# NUC400_v1 register map
File version: 1.0
Registers are 32-bit, read-write, reset 0x0 unless marked. A register's access mark holds for its fields unless they carry their own. Offsets are from the block's base; [hi:lo] are bit positions.

## CRC — CRC Register Map
Base 0x40031000
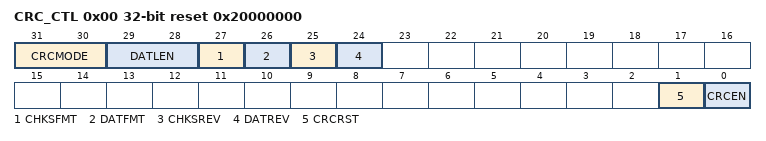
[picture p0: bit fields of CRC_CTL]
0x00 CRC_CTL reset 0x20000000 — CRC Control Register
  [31:30] CRCMODE — CRC Polynomial Mode Selection
    0=CRC-CCITT Polynomial mode; 1=CRC-8 Polynomial mode; 2=CRC-16 Polynomial mode; 3=CRC-32 Polynomial mode
  [29:28] DATLEN — CPU Write Data Length. This field indicates the write data length. Note: When the data length is 8-bit mode, the valid data is DATA [7:0]; if the data length is 16-bit mode, the valid data is DATA [15:0].
    0=Data length is 8-bit mode; 1=Data length is 16-bit mode. Data length is 32-bit mode
  [27] CHKSFMT — Checksum Complement
    0=No bit order reverse for CRC checksum; 1=1's complement for CRC checksum
  [26] DATFMT — Write Data Complement
    0=No bit order reversed for CRC write data in; 1=1's complement for CRC write data in
  [25] CHKSREV — Checksum Reverse. Note: If the checksum data is 0XDD7B0F2E, the bit order reversed for CRC checksum is 0x74F0DEBB.
    0=No bit order reverse for CRC checksum; 1=Bit order reverse for CRC checksum
  [24] DATREV — Write Data Order Reverse. Note: If the write data is 0xAABBCCDD, the bit order reverse for CRC write data in is 0x55DD33BB
    0=No bit order reversed for CRC write data in; 1=Bit order reversed for CRC write data in (per byte)
  [1] CRCRST — CRC Engine Reset. Note: Setting this bit will reload the initial seed value.
    0=No effect; 1=Reset the internal CRC state machine and internal buffer. The contents of control register will not be cleared. This bit will automatically be cleared after few clock cycles
  [0] CRCEN — CRC Channel Enable Bit
    0=CRC function Disabled; 1=CRC function Enabled
0x04 CRC_DAT — CRC Write Data Register
  [31:0] DATA — CRC Write Data Bits. Software can write data to this field to perform CRC operation, or uses PDMA function to get the data from memory
0x08 CRC_SEED reset 0xFFFFFFFF
  [31:0] SEED — CRC Seed Bits. This field indicates the CRC seed value.
0x0C CRC_CHECKSUM ro
  [31:0] CHECKSUM — CRC Checksum Bits. This field indicates the CRC checksum.

## OPA — OPS Register Map
Base 0x40046000
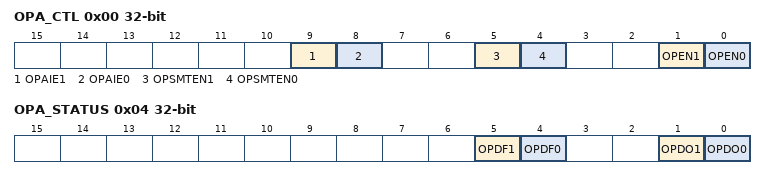
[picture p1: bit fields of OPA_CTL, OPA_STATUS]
0x00 OPA_CTL — OP Amplifier Control Register
  [9] OPAIE1 — OP Amplifier 1 Schmitt Trigger Digital Output Interrupt Enable Bit. OPDF1 interrupt flag is set by hardware whenever the OP amplifier 1 Schmitt trigger non-inverting buffer digital output changes state, in the meanwhile, if OPAIE1 is set to 1, a comparator interrupt request is generated.
    0=OP Amplifier 1 digital output interrupt function Disabled; 1=OP Amplifier 1 digital output interrupt function Enabled
  [8] OPAIE0 — OP Amplifier 0 Schmitt Trigger Digital Output Interrupt Enable Bit. The OPDF0 interrupt flag is set by hardware whenever the OP amplifier 0 Schmitt trigger non-inverting buffer digital output changes state, in the meanwhile, if OPAIE0 is set to 1, a comparator interrupt request is generated.
    0=OP Amplifier 0 digital output interrupt function Disabled; 1=OP Amplifier 0 digital output interrupt function Enabled
  [5] OPSMTEN1 — OP Amplifier 1 Schmitt Trigger Non-Inverting Buffer Enable Bit
    0=Disabled; 1=Enabled
  [4] OPSMTEN0 — OP Amplifier 0 Schmitt Trigger Non-Inverting Buffer Enable Bit
    0=Disabled; 1=Enabled
  [1] OPEN1 — OP Amplifier 1 Enable Bit. Note: OP Amplifier 1 output needs wait stable 20 s after OPEN1 is first set.
    0=Disabled; 1=Enabled
  [0] OPEN0 — OP Amplifier 0 Enable Bit. Note: OP Amplifier 0 output needs wait stable 20 s after OPEN0 is first set.
    0=Disabled; 1=Enabled
0x04 OPA_STATUS — OP Amplifier Status Register
  [5] OPDF1 — OP Amplifier 1 Schmitt Trigger Digital Output Interrupt Flag. OPDF1 interrupt flag is set by hardware whenever the OP amplifier 1 Schmitt trigger non-inverting buffer digital output changes state. This bit is cleared by writing 1 to it.
  [4] OPDF0 — OP Amplifier 0 Schmitt Trigger Digital Output Interrupt Flag. OPDF0 interrupt flag is set by hardware whenever the OP amplifier 0 Schmitt trigger non-inverting buffer digital output changes state. This bit is cleared by writing 1 to it.
  [1] OPDO1 — OP Amplifier 1 Digital Output
  [0] OPDO0 — OP Amplifier 0 Digital Output
